# bcm2711_hpa register map
Vendor: BROADCOM; Series: BCM2711; File version: A
BCM2711 found in the Raspberry Pi 4
CPU: CA72 r0p0, little endian
Registers are 32-bit, read-write, reset 0x0 unless marked. A register's access mark holds for its fields unless they carry their own. Offsets are from the block's base; lines under a group give offsets from that group; [hi:lo] are bit positions; {n}, {i} and the like mark numbered series; 'fields as' and 'values as' point back to an identical list; <NAME> marks a mode.

## Memory map
0x47E003000 SYSTMR size 0x80 — Broadcom System Timer
0x47E00B880 VCMAILBOX size 0x40 — Mailboxes for talking to/from VideoCore
0x47E101098 CM_PCM size 0x8 — Broadcom Clock Manager
0x47E1010A0 CM_PWM size 0x8
0x47E200000 GPIO size 0xF4 — Pin level and mux control
0x47E201000 UART0 blocks up to offset 0x4C — ARM Prime Cell PL011
0x47E201400 UART2 blocks up to offset 0x4C
0x47E201600 UART3 blocks up to offset 0x4C
0x47E201800 UART4 blocks up to offset 0x4C
0x47E201A00 UART5 blocks up to offset 0x4C
0x47E204000 SPI0 size 0x200 — Broadcom SPI Controller
0x47E204600 SPI3 size 0x200
0x47E204800 SPI4 size 0x200
0x47E204A00 SPI5 size 0x200
0x47E204C00 SPI6 size 0x200
0x47E204E00 PACTL size 0x40 — Interrupt status of new peripherals
0x47E205000 BSC0 size 0x200 — Broadcom Serial Controller (I2C compatible)
0x47E205600 BSC3 size 0x200
0x47E205800 BSC4 size 0x200
0x47E205A00 BSC5 size 0x200
0x47E205C00 BSC6 size 0x200
0x47E20C000 PWM0 size 0x80 — Broadcom PWM
0x47E20C800 PWM1 size 0x80
0x47E215000 AUX size 0x40 — Three auxiliary peripherals
0x47E215040 UART1 size 0x40 — Mini UART
0x47E215080 SPI1 size 0x40 — Aux SPI
0x47E2150C0 SPI2 size 0x40 — Aux SPI
0x47E300000 EMMC size 0x100 — Arasan SD3.0 Host AHB eMMC 4.4
0x47E804000 BSC1 size 0x200
0x47E980000 USB_OTG_GLOBAL size 0x131 — USB on the go high speed
0x47E980400 USB_OTG_HOST size 0x400 — USB on the go high speed
0x47E980800 USB_OTG_DEVICE size 0x400 — USB on the go high speed
0x47E980E00 USB_OTG_PWRCLK size 0x400 — USB on the go high speed power control
0x4C0000000 LIC size 0x400 — Broadcom Legacy Interrupt Controller
0x4C0041000 GIC_DIST size 0x1000 — ARM GIC-400 Generic Interrupt Controller Distributor
0x4C0042000 GIC_CPU size 0x2000 — ARM GIC-400 Generic Interrupt Controller CPU Interface

## Interrupts
{n} SGI{n} (GIC_DIST) (n=0..15) — Software generated interrupt {n}
62 EMMC — OR of EMMC and EMMC2
96 TIMER_0 (SYSTMR) — Timer 0 matched
97 TIMER_1 (SYSTMR) — Timer 1 matched
98 TIMER_2 (SYSTMR) — Timer 2 matched
99 TIMER_3 (SYSTMR) — Timer 3 matched
105 USB (USB_OTG_GLOBAL) — USB interrupt
125 AUX — Interrupt from AUX
145 GPIO0 (GPIO) — Interrupt from bank 0
146 GPIO1 (GPIO) — Interrupt from bank 1
147 GPIO2 (GPIO) — Interrupt from bank 2
148 GPIO — OR of all GPIO interrupts
149 I2C (PACTL) — OR of all I2C interrupts
150 SPI (PACTL) — OR of all SPI interrupts except 1 and 2
153 UART (PACTL) — OR of all UART interrupts except 1

## VCMAILBOX — Mailboxes for talking to/from VideoCore
Base 0x47E00B880
0x00 READ ro reset not defined — Read messages from the VideoCore
0x10 PEEK0 access not given reset not defined
0x14 SENDER0 access not given reset not defined
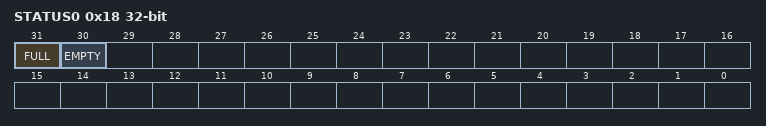
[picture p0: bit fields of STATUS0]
0x18 STATUS0 ro reset not defined
  [31] FULL, [30] EMPTY
0x1C CONFIG0 reset not defined
  [0] IRQEN — Enable the interrupt when data is available
0x20 WRITE wo reset not defined — Write messages to the VideoCore
0x30 PEEK1 access not given reset not defined
0x34 SENDER1 access not given reset not defined
0x38 STATUS1 access not given reset not defined
0x3C CONFIG1 access not given reset not defined

## CM_PCM — Broadcom Clock Manager
Base 0x47E101098
Same registers: CM_PWM 0x47E1010A0
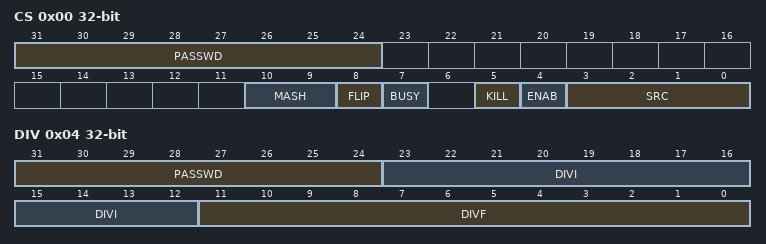
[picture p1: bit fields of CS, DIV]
0x00 CS — Control / Status
  [31:24] PASSWD wo — Password. Always 0x5a
    90=PASSWD
  [10:9] MASH — MASH control, stage count
  [8] FLIP — Generate an edge on output. (For testing)
  [7] BUSY ro — Indicates the clock generator is running
  [5] KILL — Stop and reset the generator
  [4] ENAB — Enable the clock generator. (Switch SRC first.)
  [3:0] SRC — Clock source
    other=GND; 1=XOSC; 2=TEST0; 3=TEST1; 4=PLLA; 5=PLLB; 6=PLLC; 7=HDMI
0x04 DIV — Clock divisor
  [31:24] PASSWD wo — Password. Always 0x5a
    90=PASSWD
  [23:12] DIVI — Integer part of divisor
  [11:0] DIVF — Fractional part of divisor
